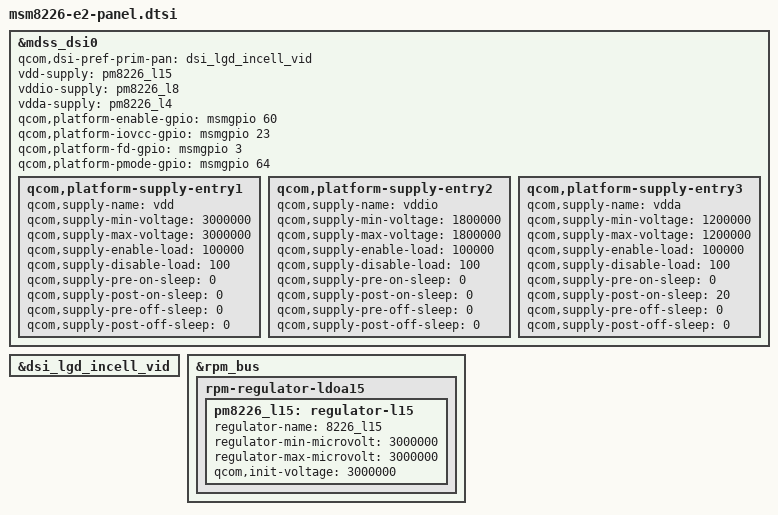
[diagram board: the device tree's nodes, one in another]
/* Copyright (c) 2013, Code Aurora Forum. All rights reserved.
 *
 * This program is free software; you can redistribute it and/or modify
 * it under the terms of the GNU General Public License version 2 and
 * only version 2 as published by the Free Software Foundation.
 *
 * This program is distributed in the hope that it will be useful,
 * but WITHOUT ANY WARRANTY; without even the implied warranty of
 * MERCHANTABILITY or FITNESS FOR A PARTICULAR PURPOSE.  See the
 * GNU General Public License for more details.
 */

&mdss_dsi0{
	qcom,dsi-pref-prim-pan = <&dsi_lgd_incell_vid>;
};

&dsi_lgd_incell_vid {
};

&mdss_dsi0 {
		vdd-supply = <&pm8226_l15>;
		vddio-supply = <&pm8226_l8>;
		vdda-supply = <&pm8226_l4>;
		qcom,platform-enable-gpio = <&msmgpio 60 0>;
		qcom,platform-iovcc-gpio = <&msmgpio 23 0>;
		qcom,platform-fd-gpio = <&msmgpio 3 0>;
		qcom,platform-pmode-gpio = <&msmgpio 64 0>;
		qcom,platform-supply-entry1 {
			qcom,supply-name = "vdd";
			qcom,supply-min-voltage = <3000000>;/*<2800000>;*/
			qcom,supply-max-voltage = <3000000>;/*<2800000>;*/
			qcom,supply-enable-load = <100000>;
			qcom,supply-disable-load = <100>;
			qcom,supply-pre-on-sleep = <0>;
			qcom,supply-post-on-sleep = <0>;
			qcom,supply-pre-off-sleep = <0>;
			qcom,supply-post-off-sleep = <0>;
		};
		qcom,platform-supply-entry2 {
			qcom,supply-name = "vddio";
			qcom,supply-min-voltage = <1800000>;
			qcom,supply-max-voltage = <1800000>;
			qcom,supply-enable-load = <100000>;
			qcom,supply-disable-load = <100>;
			qcom,supply-pre-on-sleep = <0>;
			qcom,supply-post-on-sleep = <0>;
			qcom,supply-pre-off-sleep = <0>;
			qcom,supply-post-off-sleep = <0>;
		};
		qcom,platform-supply-entry3 {
			qcom,supply-name = "vdda";
			qcom,supply-min-voltage = <1200000>;
			qcom,supply-max-voltage = <1200000>;
			qcom,supply-enable-load = <100000>;
			qcom,supply-disable-load = <100>;
			qcom,supply-pre-on-sleep = <0>;
			qcom,supply-post-on-sleep = <20>;
			qcom,supply-pre-off-sleep = <0>;
			qcom,supply-post-off-sleep = <0>;
		};
	};

/* RPM controlled regulators: */

&rpm_bus {
	rpm-regulator-ldoa15 {
		status = "okay";
		pm8226_l15: regulator-l15 {
			regulator-name = "8226_l15";
			regulator-min-microvolt = <3000000>;/*<2800000>;*/
			regulator-max-microvolt = <3000000>;/*<2800000>;*/
			qcom,init-voltage = <3000000>;/*<2800000>;*/
			status = "okay";
		};
	};
};
